# EDMA3CC register map
Vendor: Texas Instruments
Registers are 32-bit, access per field, no defined reset value unless marked. A register's access mark holds for its fields unless they carry their own. Offsets are as the file gives them; [hi:lo] are bit positions; lines under a group give offsets from that group; {n}, {i} and the like mark numbered series; 'fields as' and 'values as' point back to an identical list.

## EDMA3CC (part 2 of 2)
0x00 PID 16-bit ro — The peripheral identification register (PID) uniquely identifies the EDMA3CC and the specific revision of the EDMA3CC.
  [15:0] PID — Peripheral identifier uniquely identifies the EDMA3CC and the specific revision of the EDMA3CC. Peripheral identifier uniquely identifies the EDMA3CC and the specific revision of the EDMA3CC. Value 0 to FFFF FFFFh. Reset value for PID[31] to PID[16] is 4001h. Reset value for PID[15] to PID[0] is 1B00h.
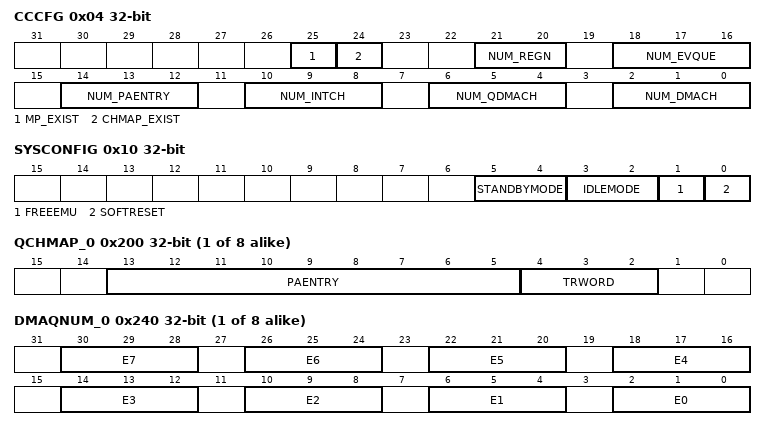
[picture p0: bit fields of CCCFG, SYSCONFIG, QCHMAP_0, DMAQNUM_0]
0x04 CCCFG ro — The EDMA3CC configuration register (CCCFG) provides the features/resources for the EDMA3CC in a particular device.
  [25] MP_EXIST — Memory protection existence.
  [24] CHMAP_EXIST — Channel mapping existence.
  [21:20] NUM_REGN — Number of MP and shadow regions.
  [18:16] NUM_EVQUE — Number of queues/number of TCs.
  [14:12] NUM_PAENTRY — Number of PaRAM sets.
  [10:8] NUM_INTCH — Number of interrupt channels.
  [6:4] NUM_QDMACH — Number of QDMA channels.
  [2:0] NUM_DMACH — Number of DMA channels.
0x10 SYSCONFIG — The EDMA3CC system configuration register is used for clock management configuration.
  [5:4] STANDBYMODE rw — Configuration of the local initiator state management mode. By definition, initiator may generate read/write transaction as long as it is out of STANDBY state.
  [3:2] IDLEMODE rw — Configuration of the local target state management mode. By definition, target can handle read/write transaction as long as it is out of IDLE state.
  [1] FREEEMU rw — Sensitivity to emulation (debug) suspend input signal.
  [0] SOFTRESET rw — Software reset (optional).
{0x100+4i} DCHMAP_{i} (i=0..63)
  [13:5] PAENTRY rw — Points to the PaRAM set number for DMA channel n. Value 0 to FFh.
{0x200+4i} QCHMAP_{i} (i=0..7) — Each QDMA channel in EDMA3CC can be associated with any PaRAM set available on the device. Furthermore, the specific trigger word (0-7) of the PaRAM set can be programmed. The PaRAM set association and trigger word for every QDMA channel register is configurable using the QDMA channel map register (QCHMAPn). At reset the QDMA channel map registers for all QDMA channels point to PaRAM set 0. If an application makes use of both a DMA channel that points to PaRAM set 0 and any QDMA channels, ensure that QCHMAP is programmed appropriately to point to a different PaRAM entry.
  [13:5] PAENTRY rw — PAENTRY points to the PaRAM set number for QDMA channel .
  [4:2] TRWORD rw — Points to the specific trigger word of the PaRAM set defined by PAENTRY. A write to the trigger word results in a QDMA event being recognized.
{0x240+4i} DMAQNUM_{i} (i=0..7) — The DMA channel queue number register (DMAQNUMn) allows programmability of each of the 64 DMA channels in the EDMA3CC to submit its associated synchronization event to any event queue in the EDMA3CC. At reset, all channels point to event queue 0. Because the event queues in EDMA3CC have a fixed association to the transfer controllers, that is, Q0 TRs are submitted to TC0, Q1 TRs are submitted to TC1, etc., by programming DMAQNUM for a particular DMA channel also dictates which transfer controller is utilized for the data movement (or which EDMA3TC receives the TR request).
  [4n+2:4n] E{n} rw (n=0..7) — DMA queue number. Contains the event queue number to be used for the corresponding DMA channel. Programming DMAQNUM for an event queue number to a value more then the number of queues available in the EDMA3CC results in undefined behavior. On DMAQNUM0, E[{4n+2}] to E[{4n}] is E{n}. On DMAQNUM1, E[{4n+2}] to E[{4n}] is E{n+8}. On DMAQNUM2, E[{4n+2}] to E[{4n}] is E{n+16}. On DMAQNUM3, E[{4n+2}] to E[{4n}] is E{n+24}. On DMAQNUM4, E[{4n+2}] to E[{4n}] is E{n+32}. On DMAQNUM5, E[{4n+2}] to E[{4n}] is E{n+40}. On DMAQNUM6, E[{4n+2}] to E[{4n}] is E{n+48}. On DMAQNUM7, E[{4n+2}] to E[{4n}] is E{n+56}.
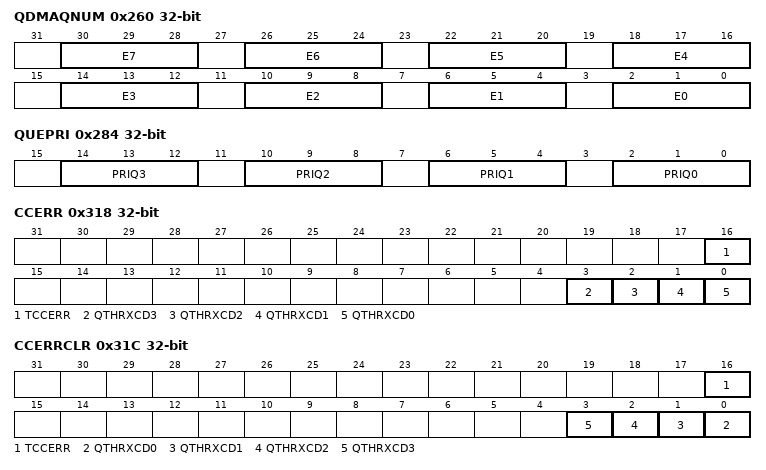
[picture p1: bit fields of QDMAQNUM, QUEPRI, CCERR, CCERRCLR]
0x260 QDMAQNUM — The QDMA channel queue number register (QDMAQNUMn) is used to program all the QDMA channels in the EDMA3CC to submit the associated QDMA event to any of the event queues in the EDMA3CC.
  [4n+2:4n] E{n} rw (n=0..7) — QDMA queue number. Contains the event queue number to be used for the corresponding QDMA channel.
0x284 QUEPRI — The queue priority register (QUEPRI) allows you to change the priority of the individual queues and the priority of the transfer request (TR) associated with the events queued in the queue. Because the queue to EDMA3TC mapping is fixed, programming QUEPRI essentially governs the priority of the associated transfer controller(s) read/write commands with respect to the other bus masters in the device. You can modify the EDMA3TC priority to obtain the desired system performance.
  [4n+2:4n] PRIQ{n} rw (n=0..3) — Priority level for queue {n}. Dictates the priority level used by TC{n} relative to other masters in the device. A value of 0 means highest priority and a value of 7 means lowest priority.
0x300 EMR ro — For a particular DMA channel, if a second event is received prior to the first event getting cleared/serviced, the bit corresponding to that channel is set/asserted in the event missed registers (EMR/EMRH). All trigger types are treated individually, that is, manual triggered (ESR/ESRH), chain triggered (CER/CERH), and event triggered (ER/ERH) are all treated separately. The EMR/EMRH bits for a channel are also set if an event on that channel encounters a NULL entry (or a NULL TR is serviced). If any EMR/EMRH bit is set (and all errors, including bits in other error registers (QEMR, CCERR) were previously cleared), the EDMA3CC generates an error interrupt. For details on EDMA3CC error interrupt generation, see Error Interrupts. This register is part of a set of registers that provide information on missed DMA and/or QDMA events, and instances when event queue thresholds are exceeded. If any of the bits in these registers is set, it results in the EDMA3CC generating an error interrupt.
  [31:0] En — Channel 0 to 31 event missed. En is cleared by writing a 1 to the corresponding bit in the event missed clear register (EMCR).
0x304 EMRH ro — For a particular DMA channel, if a second event is received prior to the first event getting cleared/serviced, the bit corresponding to that channel is set/asserted in the event missed registers (EMR/EMRH). All trigger types are treated individually, that is, manual triggered (ESR/ESRH), chain triggered (CER/CERH), and event triggered (ER/ERH) are all treated separately. The EMR/EMRH bits for a channel are also set if an event on that channel encounters a NULL entry (or a NULL TR is serviced). If any EMR/EMRH bit is set (and all errors, including bits in other error registers (QEMR, CCERR) were previously cleared), the EDMA3CC generates an error interrupt. For details on EDMA3CC error interrupt generation, see Error Interrupts. This register is part of a set of registers that provide information on missed DMA and/or QDMA events, and instances when event queue thresholds are exceeded. If any of the bits in these registers is set, it results in the EDMA3CC generating an error interrupt.
  [31:0] En — Channel 32 to 63 event missed. En is cleared by writing a 1 to the corresponding bit in the event missed clear register high (EMCRH).
0x308 EMCR wo — Once a missed event is posted in the event missed registers (EMR/EMRH), the bit remains set and you need to clear the set bit(s). This is done by way of CPU writes to the event missed clear registers (EMCR/EMCRH). Writing a 1 to any of the bits clears the corresponding missed event (bit) in EMR/EMRH; writing a 0 has no effect. This register is part of a set of registers that provide information on missed DMA and/or QDMA events, and instances when event queue thresholds are exceeded. If any of the bits in these registers is set, it results in the EDMA3CC generating an error interrupt.
  [31:0] En — Event missed 0 to 31 clear. All error bits must be cleared before additional error interrupts will be asserted by the EDMA3CC.
0x30C EMCRH wo — Once a missed event is posted in the event missed registers (EMR/EMRH), the bit remains set and you need to clear the set bit(s). This is done by way of CPU writes to the event missed clear registers (EMCR/EMCRH). Writing a 1 to any of the bits clears the corresponding missed event (bit) in EMR/EMRH; writing a 0 has no effect. This register is part of a set of registers that provide information on missed DMA and/or QDMA events, and instances when event queue thresholds are exceeded. If any of the bits in these registers is set, it results in the EDMA3CC generating an error interrupt.
  [31:0] En — Event missed 32 to 63 clear. All error bits must be cleared before additional error interrupts will be asserted by the EDMA3CC.
0x310 QEMR ro — For a particular QDMA channel, if two QDMA events are detected without the first event getting cleared/serviced, the bit corresponding to that channel is set/asserted in the QDMA event missed register (QEMR). The QEMR bits for a channel are also set if a QDMA event on the channel encounters a NULL entry (or a NULL TR is serviced). If any QEMR bit is set (and all errors, including bits in other error registers (EMR/EMRH, CCERR) were previously cleared), the EDMA3CC generates an error interrupt. For details on EDMA3CC error interrupt generation, see Error Interrupts. This register is part of a set of registers that provide information on missed DMA and/or QDMA events, and instances when event queue thresholds are exceeded. If any of the bits in these registers is set, it results in the EDMA3CC generating an error interrupt.
  [7:0] En — Channel 0 to 7 QDMA event missed. En is cleared by writing a 1 to the corresponding bit in the QDMA event missed clear register (QEMCR).
0x314 QEMCR — Once a missed event is posted in the QDMA event missed registers (QEMR), the bit remains set and you need to clear the set bit(s). This is done by way of CPU writes to the QDMA event missed clear registers (QEMCR). Writing a 1 to any of the bits clears the corresponding missed event (bit) in QEMR; writing a 0 has no effect. This register is part of a set of registers that provide information on missed DMA and/or QDMA events, and instances when event queue thresholds are exceeded. If any of the bits in these registers is set, it results in the EDMA3CC generating an error interrupt.
  [7:0] En wo — QDMA event missed clear. All error bits must be cleared before additional error interrupts will be asserted by the EDMA3CC.
0x318 CCERR ro — The EDMA3CC error register (CCERR) indicates whether or not at any instant of time the number of events queued up in any of the event queues exceeds or equals the threshold/watermark value that is set in the queue watermark threshold register (QWMTHRA). Additionally, CCERR also indicates if when the number of outstanding TRs that have been programmed to return transfer completion code (TRs which have the TCINTEN or TCCHEN bit in OPT set) to the EDMA3CC has exceeded the maximum allowed value of 63. If any bit in CCERR is set (and all errors, including bits in other error registers (EMR/EMRH, QEMR) were previously cleared), the EDMA3CC generates an error interrupt. For details on EDMA3CC error interrupt generation, see Error Interrupts. Once the error bits are set in CCERR, they can only be cleared by writing to the corresponding bits in the EDMA3CC error clear register (CCERRCLR). This register is part of a set of registers that provide information on missed DMA and/or QDMA events, and instances when event queue thresholds are exceeded. If any of the bits in these registers is set, it results in the EDMA3CC generating an error interrupt.
  [16] TCCERR — Transfer completion code error. TCCERR is cleared by writing a 1 to the corresponding bit in the EDMA3CC error clear register (CCERRCLR).
  [3] QTHRXCD3 — Queue threshold error for queue 3. QTHRXCD3 is cleared by writing a 1 to the corresponding bit in the EDMA3CC error clear register (CCERRCLR).
  [2] QTHRXCD2 — Queue threshold error for queue 2. QTHRXCD2 is cleared by writing a 1 to the corresponding bit in the EDMA3CC error clear register (CCERRCLR).
  [1] QTHRXCD1 — Queue threshold error for queue 1 . QTHRXCD1 is cleared by writing a 1 to the corresponding bit in the EDMA3CC error clear register (CCERRCLR).
  [0] QTHRXCD0 — Queue threshold error for queue 0. QTHRXCD0 is cleared by writing a 1 to the corresponding bit in the EDMA3CC error clear register (CCERRCLR).
0x31C CCERRCLR — The EDMA3CC error clear register (CCERRCLR) is used to clear any error bits that are set in the EDMA3CC error register (CCERR). In addition, CCERRCLR also clears the values of some bit fields in the queue status registers (QSTATn) associated with a particular event queue. Writing a 1 to any of the bits clears the corresponding bit in CCERR; writing a 0 has no effect. This register is part of a set of registers that provide information on missed DMA and/or QDMA events, and instances when event queue thresholds are exceeded. If any of the bits in these registers is set, it results in the EDMA3CC generating an error interrupt.
  [16] TCCERR wo — Transfer completion code error clear.
  [n] QTHRXCD{n} wo (n=0..3) — Queue threshold error clear for queue {n}.
0x320 EEVAL — The EDMA3CC error interrupt is asserted whenever an error bit is set in any of the error registers (EMR/EMRH, QEMR, and CCERR). For subsequent error bits that get set, the EDMA3CC error interrupt is reasserted only when transitioning from an all the error bits cleared to at least one error bit is set . Alternatively, a CPU write of 1 to the EVAL bit in the error evaluation register (EEVAL) results in reasserting the EDMA3CC error interrupt, if there are any outstanding error bits set due to subsequent error conditions. Writes of 0 have no effect. This register is part of a set of registers that provide information on missed DMA and/or QDMA events, and instances when event queue thresholds are exceeded. If any of the bits in these registers is set, it results in the EDMA3CC generating an error interrupt.
  [0] EVAL wo — Error interrupt evaluate.
{0x340+8i} DRAE{i} rw (i=0..7) — The DMA region access enable register for shadow region {i} is programmed to allow or disallow read/write accesses on a bit-by-bit bases for all DMA registers in the shadow region {i} view of the DMA channel registers. Additionally, the DRAE{i} configuration determines completion of which DMA channels will result in assertion of the shadow region {i} DMA completion interrupt. The DRAE registers are part of the group of the region access enable registers, which includes DRAEm and QRAEm. Where m is the number of shadow regions in the EDMA3CC memory map for a device. You can configure these registers to assign ownership of DMA/QDMA channels to a particular shadow region.
  [31:0] En — DMA region access enable for bit 31 to 0 in region {i}.
{0x344+8i} DRAEH{i} rw (i=0..7) — The DMA region access enable register for shadow region {i} is programmed to allow or disallow read/write accesses on a bit-by-bit bases for all DMA registers in the shadow region {i} view of the DMA channel registers. Additionally, the DRAE{i} configuration determines completion of which DMA channels will result in assertion of the shadow region {i} DMA completion interrupt. The DRAE registers are part of the group of the region access enable registers, which includes DRAEm and QRAEm. Where m is the number of shadow regions in the EDMA3CC memory map for a device. You can configure these registers to assign ownership of DMA/QDMA channels to a particular shadow region.
  [31:0] En — DMA region access enable for bit 63 to 32 in region {i}.
{0x380+4i} QRAE_{i} (i=0..7) — The QDMA region access enable register for shadow region m (QRAEm) is programmed to allow or disallow read/write accesses on a bit-by-bit bases for all QDMA registers in the shadow region m view of the QDMA registers. This includes all 4-bit QDMA registers. The QRAE register is part of the group of the region access enable registers, which includes DRAEm and QRAEm. Where m is the number of shadow regions in the EDMA3CC memory map for a device. You can configure these registers to assign ownership of DMA/QDMA channels to a particular shadow region.
  [7:0] En rw — QDMA region access enable for bit n/QDMA channel n in region m.
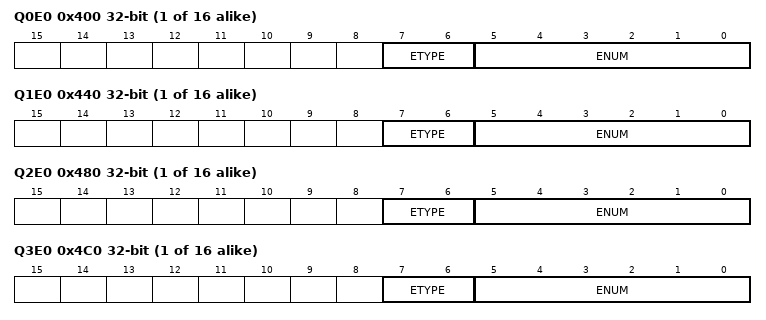
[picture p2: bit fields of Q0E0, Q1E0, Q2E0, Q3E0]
{0x400+4i} Q0E{i} ro (i=0..15) — The event queue entry registers (QxEy) exist for all 16 queue entries (the maximum allowed queue entries) for all event queues in the EDMA3CC. The event queue entry registers range from Q0E0 to Q0E15, Q1E0 to Q1E15, Q2E0 to Q2E15, and Q3E0 to Q3E15. Each register details the event number (ENUM) and the event type (ETYPE). For example, if the value in Q1E4 is read as 000 004Fh, this means the 4th entry in queue 1 is a manually-triggered event on DMA channel 15. The Q0E{i} register provides visibility into the event queues and a TR life cycle. These are useful for system debug as they provide in-depth visibility for the events queued up in the event queue and also provide information on what parts of the EDMA3CC logic are active once the event has been received by the EDMA3CC.
  [7:6] ETYPE — Event entry {i} in queue 0. Specifies the specific event type for the given entry in the event queue.
  [5:0] ENUM — Event entry {i} in queue 0. Event number: QDMA channel number (0 to 3). DMA channel/event number (0 to 63).
{0x440+4i} Q1E{i} ro (i=0..15) — The event queue entry registers (QxEy) exist for all 16 queue entries (the maximum allowed queue entries) for all event queues in the EDMA3CC. The event queue entry registers range from Q0E0 to Q0E15, Q1E0 to Q1E15, Q2E0 to Q2E15, and Q3E0 to Q3E15. Each register details the event number (ENUM) and the event type (ETYPE). For example, if the value in Q1E4 is read as 000 004Fh, this means the 4th entry in queue 1 is a manually-triggered event on DMA channel 15. The Q1E{i} register provides visibility into the event queues and a TR life cycle. These are useful for system debug as they provide in-depth visibility for the events queued up in the event queue and also provide information on what parts of the EDMA3CC logic are active once the event has been received by the EDMA3CC.
  [7:6] ETYPE — Event entry {i} in queue 1. Specifies the specific event type for the given entry in the event queue.
  [5:0] ENUM — Event entry {i} in queue 1. Event number: QDMA channel number (0 to 3). DMA channel/event number (0 to 63).
{0x480+4i} Q2E{i} ro (i=0..15) — The event queue entry registers (QxEy) exist for all 16 queue entries (the maximum allowed queue entries) for all event queues in the EDMA3CC. The event queue entry registers range from Q0E0 to Q0E15, Q1E0 to Q1E15, Q2E0 to Q2E15, and Q3E0 to Q3E15. Each register details the event number (ENUM) and the event type (ETYPE). For example, if the value in Q1E4 is read as 000 004Fh, this means the 4th entry in queue 1 is a manually-triggered event on DMA channel 15. The Q2E{i} register provides visibility into the event queues and a TR life cycle. These are useful for system debug as they provide in-depth visibility for the events queued up in the event queue and also provide information on what parts of the EDMA3CC logic are active once the event has been received by the EDMA3CC.
  [7:6] ETYPE — Event entry {i} in queue 2. Specifies the specific event type for the given entry in the event queue.
  [5:0] ENUM — Event entry {i} in queue 2. Event number: QDMA channel number (0 to 3). DMA channel/event number (0 to 63).
{0x4C0+4i} Q3E{i} ro (i=0..15) — The event queue entry registers (QxEy) exist for all 16 queue entries (the maximum allowed queue entries) for all event queues in the EDMA3CC. The event queue entry registers range from Q0E0 to Q0E15, Q1E0 to Q1E15, Q2E0 to Q2E15, and Q3E0 to Q3E15. Each register details the event number (ENUM) and the event type (ETYPE). For example, if the value in Q1E4 is read as 000 004Fh, this means the 4th entry in queue 1 is a manually-triggered event on DMA channel 15. The Q3E{i} register provides visibility into the event queues and a TR life cycle. These are useful for system debug as they provide in-depth visibility for the events queued up in the event queue and also provide information on what parts of the EDMA3CC logic are active once the event has been received by the EDMA3CC.
  [7:6] ETYPE — Event entry {i} in queue 3. Specifies the specific event type for the given entry in the event queue.
  [5:0] ENUM — Event entry {i} in queue 3. Event number: QDMA channel number (0 to 3). DMA channel/event number (0 to 63).
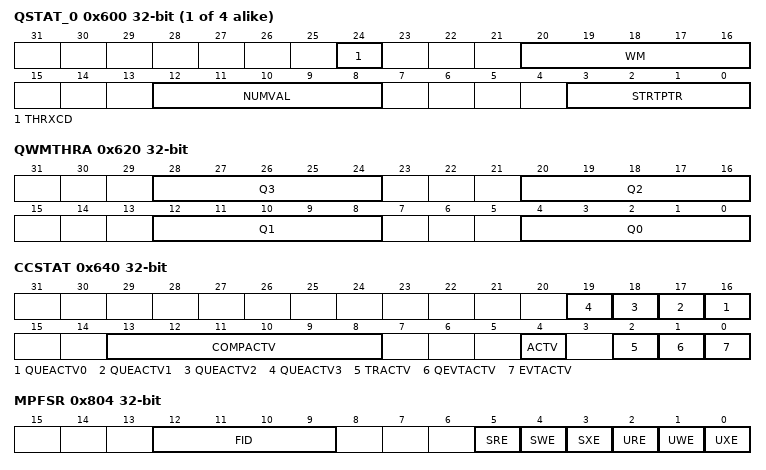
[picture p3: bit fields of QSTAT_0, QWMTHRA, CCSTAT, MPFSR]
{0x600+4i} QSTAT_{i} ro (i=0..3) — The queue status register (QSTAT) provides visibility into the event queues and a TR life cycle. These are useful for system debug as they provide in-depth visibility for the events queued up in the event queue and also provide information on what parts of the EDMA3CC logic are active once the event has been received by the EDMA3CC.
  [24] THRXCD — Threshold exceeded. THRXCD is cleared by writing a 1 to the corresponding QTHRXCDn bit in the EDMA3CC error clear register (CCERRCLR).
  [20:16] WM — Watermark for maximum queue usage. Watermark tracks the most entries that have been in queue n since reset or since the last time that the watermark (WM) bit was cleared. WM is cleared by writing a 1 to the corresponding QTHRXCDn bit in the EDMA3CC error clear register (CCERRCLR).
  [12:8] NUMVAL — Number of valid entries in queue n. The total number of entries residing in the queue manager FIFO at a given instant. Always enabled.
  [3:0] STRTPTR — Start pointer. The offset to the head entry of queue n, in units of entries. Always enabled. Legal values are 0 (0th entry) to Fh (15th entry).
0x620 QWMTHRA — The queue watermark threshold A register (QWMTHRA) provides visibility into the event queues and a TR life cycle. These are useful for system debug as they provide in-depth visibility for the events queued up in the event queue and also provide information on what parts of the EDMA3CC logic are active once the event has been received by the EDMA3CC.
  [8n+4:8n] Q{n} rw (n=0..3) — Queue threshold for queue {n} value. The QTHRXCD{n} bit in the EDMA3CC error register (CCERR) and the THRXCD bit in the queue status register {n} (QSTAT{n}) are set when the number of events in queue {n} at an instant in time (visible via the NUMVAL bit in QSTAT{n}) equals or exceeds the value specified by Q{n}.
0x640 CCSTAT ro — The EDMA3CC status register (CCSTAT) has a number of status bits that reflect which parts of the EDMA3CC logic is active at any given instant of time. CCSTAT provides visibility into the event queues and a TR life cycle. These are useful for system debug as they provide in-depth visibility for the events queued up in the event queue and also provide information on what parts of the EDMA3CC logic are active once the event has been received by the EDMA3CC.
  [n+16] QUEACTV{n} (n=0..3) — Queue {n} active.
  [13:8] COMPACTV — Completion request active. The COMPACTV field reflects the count for the number of completion requests submitted to the transfer controllers. This count increments every time a TR is submitted and is programmed to report completion (the TCINTEN or TCCCHEN bits in OPT in the parameter entry associated with the TR are set). The counter decrements for every valid TCC received back from the transfer controllers. If at any time the count reaches a value of 63, the EDMA3CC will not service any new TRs until the count is less then 63 (or return a transfer completion code from a transfer controller, which would decrement the count).
  [4] ACTV — Channel controller active. Channel controller active is a logical-OR of each of the *ACTV bits. The ACTV bit remains high through the life of a TR.
  [2] TRACTV — Transfer request active.
  [1] QEVTACTV — QDMA event active.
  [0] EVTACTV — DMA event active.
0x800 MPFAR ro — A CPU write of 1 to the MPFCLR bit in the memory protection fault command register (MPFCR) causes any error conditions stored in MPFAR to be cleared.
  [31:0] FADDR — Fault address. This 32 bit read-only status register contains the fault address when a memory protection violation is detected. This register can only be cleared via the memory protection fault command register (MPFCR). Value 0 to FFFF FFFFh.
0x804 MPFSR ro — A CPU write of 1 to the MPFCLR bit in the memory protection fault command register (MPFCR) causes any error conditions stored in MPFSR to be cleared.
  [12:9] FID — Faulted identification. FID contains valid information if any of the MP error bits (UXE, UWE, URE, SXE, SWE, SRE) are nonzero (that is, if an error has been detected.) The FID field contains the privilege ID for the specific request/requestor that resulted in an MP error. Value 0 to Fh.
  [5] SRE — Supervisor read error.
  [4] SWE — Supervisor write error.
  [3] SXE — Supervisor execute error.
  [2] URE — User read error.
  [1] UWE — User write error.
  [0] UXE — User execute error.
0x808 MPFCR
  [0] MPFCLR wo — Fault clear register.
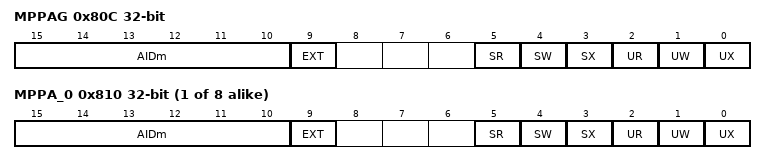
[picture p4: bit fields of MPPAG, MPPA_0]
0x80C MPPAG
  [15:10] AIDm rw — Allowed ID 'N'
  [9] EXT rw — External Allowed ID.
  [5] SR rw — Supervisor read permission.
  [4] SW rw — Supervisor write permission.
  [3] SX rw — Supervisor execute permission.
  [2] UR rw — User read permission.
  [1] UW rw — User write permission.
  [0] UX rw — User execute permission.
{0x810+4i} MPPA_{i} (i=0..7)
  fields as MPPAG
0x1000 ER ro — All external events are captured in the event register (ER/ERH). The events are latched even when the events are not enabled. If the event bit corresponding to the latched event is enabled (EER.En/EERH.En = 1), then the event is evaluated by the EDMA3CC logic for an associated transfer request submission to the transfer controllers. The event register bits are automatically cleared (ER.En/ERH.En= 0) once the corresponding events are prioritized and serviced. If ER.En/ERH.En are already set and another event is received on the same channel/event, then the corresponding event is latched in the event miss register (EMR.En/EMRH.En), provided that the event was enabled (EER.En/EERH.En = 1). Event n can be cleared by the CPU writing a 1 to corresponding event bit in the event clear register (ECR/ECRH). The setting of an event is a higher priority relative to clear operations (via hardware or software). If set and clear conditions occur concurrently, the set condition wins. If the event was previously set, then EMR/EMRH would be set because an event is lost. If the event was previously clear, then the event remains set and is prioritized for submission to the event queues. The Debug List table provides the type of synchronization events and the EDMA3CC channels associated to each of these external events. This register is part of a set of registers that pertain to the 64 DMA channels. The 64 DMA channels consist of a set of registers (with exception of DMAQNUMn) that each have 64 bits and the bit position of each register matches the DMA channel number. Each register is named with the format reg_name that corresponds to DMA channels 0 through 31 and reg_name_High that corresponds to DMA channels 32 through 64. For example, the event register (ER) corresponds to DMA channel 0 through 31 and the event register high register (ERH) corresponds to DMA channel 32 through 63. The register is typically called the event register. The DMA channel registers are accessible via read/writes to the global address range. They are also accessible via read/writes to the shadow address range. The read/write ability to the registers in the shadow region are controlled by the DMA region access registers (DRAEm/DRAEHm).
  [31:0] En — Event 0 to 31. Events 0 to 31 are captured by the EDMA3CC and are latched into ER. The events are set (En = 1) even when events are disabled (En = 0 in the event enable register, EER).
0x1004 ERH ro — All external events are captured in the event register (ER/ERH). The events are latched even when the events are not enabled. If the event bit corresponding to the latched event is enabled (EER.En/EERH.En = 1), then the event is evaluated by the EDMA3CC logic for an associated transfer request submission to the transfer controllers. The event register bits are automatically cleared (ER.En/ERH.En= 0) once the corresponding events are prioritized and serviced. If ER.En/ERH.En are already set and another event is received on the same channel/event, then the corresponding event is latched in the event miss register (EMR.En/EMRH.En), provided that the event was enabled (EER.En/EERH.En = 1). Event n can be cleared by the CPU writing a 1 to corresponding event bit in the event clear register (ECR/ECRH). The setting of an event is a higher priority relative to clear operations (via hardware or software). If set and clear conditions occur concurrently, the set condition wins. If the event was previously set, then EMR/EMRH would be set because an event is lost. If the event was previously clear, then the event remains set and is prioritized for submission to the event queues. The Debug List table provides the type of synchronization events and the EDMA3CC channels associated to each of these external events. This register is part of a set of registers that pertain to the 64 DMA channels. The 64 DMA channels consist of a set of registers (with exception of DMAQNUMn) that each have 64 bits and the bit position of each register matches the DMA channel number. Each register is named with the format reg_name that corresponds to DMA channels 0 through 31 and reg_name_High that corresponds to DMA channels 32 through 64. For example, the event register (ER) corresponds to DMA channel 0 through 31 and the event register high register (ERH) corresponds to DMA channel 32 through 63. The register is typically called the event register. The DMA channel registers are accessible via read/writes to the global address range. They are also accessible via read/writes to the shadow address range. The read/write ability to the registers in the shadow region are controlled by the DMA region access registers (DRAEm/DRAEHm).
  [31:0] En — Event 32 to 63. Events 32 to 63 are captured by the EDMA3CC and are latched into ERH. The events are set (En = 1) even when events are disabled (En = 0 in the event enable register high, EERH).
0x1008 ECR wo — Once an event has been posted in the event registers (ER/ERH), the event is cleared in two ways. If the event is enabled in the event enable register (EER/EERH) and the EDMA3CC submits a transfer request for the event to the EDMA3TC, it clears the corresponding event bit in the event register. If the event is disabled in the event enable register (EER/EERH), the CPU can clear the event by way of the event clear registers (ECR/ECRH). Writing a 1 to any of the bits clears the corresponding event; writing a 0 has no effect. Once an event bit is set in the event register, it remains set until EDMA3CC submits a transfer request for that event or the CPU clears the event by setting the corresponding bit in ECR/ECRH. This register is part of a set of registers that pertain to the 64 DMA channels. The 64 DMA channels consist of a set of registers (with exception of DMAQNUMn) that each have 64 bits and the bit position of each register matches the DMA channel number. Each register is named with the format reg_name that corresponds to DMA channels 0 through 31 and reg_name_High that corresponds to DMA channels 32 through 64. For example, the event register (ER) corresponds to DMA channel 0 through 31 and the event register high register (ERH) corresponds to DMA channel 32 through 63. The register is typically called the event register. The DMA channel registers are accessible via read/writes to the global address range. They are also accessible via read/writes to the shadow address range. The read/write ability to the registers in the shadow region are controlled by the DMA region access registers (DRAEm/DRAEHm).
  [31:0] En — Event clear for event 0 to 31. Any of the event bits in ECR is set to clear the event (En) in the event register (ER). A write of 0 has no effect.
0x100C ECRH wo — Once an event has been posted in the event registers (ER/ERH), the event is cleared in two ways. If the event is enabled in the event enable register (EER/EERH) and the EDMA3CC submits a transfer request for the event to the EDMA3TC, it clears the corresponding event bit in the event register. If the event is disabled in the event enable register (EER/EERH), the CPU can clear the event by way of the event clear registers (ECR/ECRH). Writing a 1 to any of the bits clears the corresponding event; writing a 0 has no effect. Once an event bit is set in the event register, it remains set until EDMA3CC submits a transfer request for that event or the CPU clears the event by setting the corresponding bit in ECR/ECRH. This register is part of a set of registers that pertain to the 64 DMA channels. The 64 DMA channels consist of a set of registers (with exception of DMAQNUMn) that each have 64 bits and the bit position of each register matches the DMA channel number. Each register is named with the format reg_name that corresponds to DMA channels 0 through 31 and reg_name_High that corresponds to DMA channels 32 through 64. For example, the event register (ER) corresponds to DMA channel 0 through 31 and the event register high register (ERH) corresponds to DMA channel 32 through 63. The register is typically called the event register. The DMA channel registers are accessible via read/writes to the global address range. They are also accessible via read/writes to the shadow address range. The read/write ability to the registers in the shadow region are controlled by the DMA region access registers (DRAEm/DRAEHm).
  [31:0] En — Event clear for event 32 to 63. Any of the event bits in ECRH are set to clear the event (En) in the event register high (ERH). A write of 0 has no effect.
0x1010 ESR rw — The event set registers (ESR/ESRH) allow the CPU (EDMA3 programmers) to manually set events to initiate DMA transfer requests. CPU writes of 1 to any event set register (En) bits set the corresponding bits in the registers. The set event is evaluated by the EDMA3CC logic for an associated transfer request submission to the transfer controllers. Writing a 0 has no effect. The event set registers operate independent of the event registers (ER/ERH), and a write of 1 is always considered a valid event regardless of whether the event is enabled (the corresponding event bits are set or cleared in EER.En/EERH.En). Once the event is set in the event set registers, it cannot be cleared by CPU writes, in other words, the event clear registers (ECR/ECRH) have no effect on the state of ESR/ESRH. The bits will only be cleared once the transfer request corresponding to the event has been submitted to the transfer controller. The setting of an event is a higher priority relative to clear operations (via hardware). If set and clear conditions occur concurrently, the set condition wins. If the event was previously set, then EMR/EMRH would be set because an event is lost. If the event was previously clear, then the event remains set and is prioritized for submission to the event queues. Manually-triggered transfers via writes to ESR/ESRH allow the CPU to submit DMA requests in the system, these are relevant for memory-to-memory transfer scenarios. If the ESR.En/ESRH.En bit is already set and another CPU write of 1 is attempted to the same bit, then the corresponding event is latched in the event missed registers (EMR.En/EMRH.En = 1). This register is part of a set of registers that pertain to the 64 DMA channels. The 64 DMA channels consist of a set of registers (with exception of DMAQNUMn) that each have 64 bits and the bit position of each register matches the DMA channel number. Each register is named with the format reg_name that corresponds to DMA channels 0 through 31 and reg_name_High that corresponds to DMA channels 32 through 64. For example, the event register (ER) corresponds to DMA channel 0 through 31 and the event register high register (ERH) corresponds to DMA channel 32 through 63. The register is typically called the event register. The DMA channel registers are accessible via read/writes to the global address range. They are also accessible via read/writes to the shadow address range. The read/write ability to the registers in the shadow region are controlled by the DMA region access registers (DRAEm/DRAEHm).
  [31:0] En — Event set for event 0 to 31.
0x1014 ESRH rw — The event set registers (ESR/ESRH) allow the CPU (EDMA3 programmers) to manually set events to initiate DMA transfer requests. CPU writes of 1 to any event set register (En) bits set the corresponding bits in the registers. The set event is evaluated by the EDMA3CC logic for an associated transfer request submission to the transfer controllers. Writing a 0 has no effect. The event set registers operate independent of the event registers (ER/ERH), and a write of 1 is always considered a valid event regardless of whether the event is enabled (the corresponding event bits are set or cleared in EER.En/EERH.En). Once the event is set in the event set registers, it cannot be cleared by CPU writes, in other words, the event clear registers (ECR/ECRH) have no effect on the state of ESR/ESRH. The bits will only be cleared once the transfer request corresponding to the event has been submitted to the transfer controller. The setting of an event is a higher priority relative to clear operations (via hardware). If set and clear conditions occur concurrently, the set condition wins. If the event was previously set, then EMR/EMRH would be set because an event is lost. If the event was previously clear, then the event remains set and is prioritized for submission to the event queues. Manually-triggered transfers via writes to ESR/ESRH allow the CPU to submit DMA requests in the system, these are relevant for memory-to-memory transfer scenarios. If the ESR.En/ESRH.En bit is already set and another CPU write of 1 is attempted to the same bit, then the corresponding event is latched in the event missed registers (EMR.En/EMRH.En = 1). This register is part of a set of registers that pertain to the 64 DMA channels. The 64 DMA channels consist of a set of registers (with exception of DMAQNUMn) that each have 64 bits and the bit position of each register matches the DMA channel number. Each register is named with the format reg_name that corresponds to DMA channels 0 through 31 and reg_name_High that corresponds to DMA channels 32 through 64. For example, the event register (ER) corresponds to DMA channel 0 through 31 and the event register high register (ERH) corresponds to DMA channel 32 through 63. The register is typically called the event register. The DMA channel registers are accessible via read/writes to the global address range. They are also accessible via read/writes to the shadow address range. The read/write ability to the registers in the shadow region are controlled by the DMA region access registers (DRAEm/DRAEHm).
  [31:0] En — Event set for event 32 to 63.
